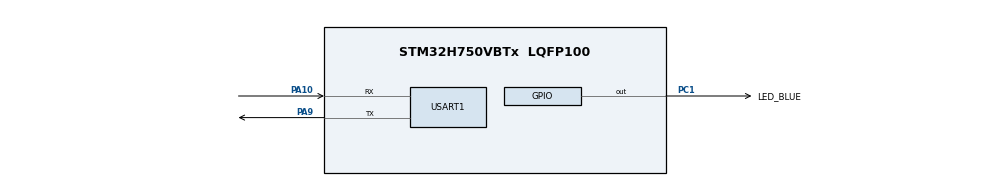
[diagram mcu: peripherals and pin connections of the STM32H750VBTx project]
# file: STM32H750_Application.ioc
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Mcu.Family=STM32H7
Mcu.Name=STM32H750VBTx
Mcu.Package=LQFP100
NVIC.PriorityGroup=NVIC_PRIORITYGROUP_4
PA10.Mode=Asynchronous
PA10.Signal=USART1_RX
PA9.Mode=Asynchronous
PA9.Signal=USART1_TX
PC1.GPIO_Label=LED_BLUE
PC1.Signal=GPIO_Output
ProjectManager.HeapSize=0x200
ProjectManager.StackSize=0x400
ProjectManager.TargetToolchain=STM32CubeIDE
RCC.ADCFreq_Value=129000000
RCC.APB1Freq_Value=120000000
RCC.APB2Freq_Value=120000000
RCC.APB3Freq_Value=120000000
RCC.APB4Freq_Value=120000000
RCC.CortexFreq_Value=480000000
RCC.D1PPRE=RCC_APB3_DIV2
RCC.D2PPRE1=RCC_APB1_DIV2
RCC.D2PPRE2=RCC_APB2_DIV2
RCC.D3PPRE=RCC_APB4_DIV2
RCC.DIVM1=4
RCC.DIVN1=60
RCC.HCLKFreq_Value=240000000
RCC.HPRE=RCC_HCLK_DIV2
RCC.PLL2FRACN=0
RCC.PLL3FRACN=0
RCC.PLLFRACN=0
RCC.PWR_Regulator_Voltage_Scale=PWR_REGULATOR_VOLTAGE_SCALE0
RCC.ProductRev=revV
RCC.SYSCLKFreq_VALUE=480000000
RCC.SYSCLKSource=RCC_SYSCLKSOURCE_PLLCLK
RCC.USBFreq_Value=480000000
USART1.VirtualMode-Asynchronous=VM_ASYNC
board=custom

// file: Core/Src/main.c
/* USER CODE BEGIN Header */
/**
  ******************************************************************************
  * @file           : main.c
  * @brief          : Main program body
  ******************************************************************************
  * @attention
  *
  * Copyright (c) 2026 STMicroelectronics.
  * All rights reserved.
  *
  * This software is licensed under terms that can be found in the LICENSE file
  * in the root directory of this software component.
  * If no LICENSE file comes with this software, it is provided AS-IS.
  *
  ******************************************************************************
  */
/* USER CODE END Header */
#include "main.h"
#include "usart.h"
#include "gpio.h"

/* USER CODE BEGIN Includes */
#include <string.h>
#include <stdio.h>
/* USER CODE END Includes */

void SystemClock_Config(void);
/* USER CODE BEGIN PFP */
void UART_SendString(UART_HandleTypeDef *huart, const char *str);
void UART_SendLine(UART_HandleTypeDef *huart, const char *str);
/* USER CODE END PFP */

/* USER CODE BEGIN 0 */

// ========== UART HELPER FUNCTIONS ==========
// Send a string via UART
void UART_SendString(UART_HandleTypeDef *huart, const char *str)
{
	uint16_t len = strlen(str);
	HAL_UART_Transmit(huart, (uint8_t *)str, len, 1000);
}

// Send a line (string + newline)
void UART_SendLine(UART_HandleTypeDef *huart, const char *str)
{
	UART_SendString(huart, str);
	UART_SendString(huart, "\r\n");
}

/* USER CODE END 0 */

int main(void)
{

  /* MCU Configuration--------------------------------------------------------*/

  /* Reset of all peripherals, Initializes the Flash interface and the Systick. */
  HAL_Init();

  /* Configure the system clock */
  SystemClock_Config();

  /* USER CODE BEGIN SysInit */

  /* Set VTOR to QSPI address where app vector table is located */
  SCB->VTOR = 0x90000000;

  /* USER CODE END SysInit */

  /* Initialize all configured peripherals */
  MX_GPIO_Init();
  MX_USART1_UART_Init();
  /* USER CODE BEGIN 2 */

  /* Debug: Add delay to ensure UART is ready after jump + bootloader DeInit */
  HAL_Delay(200);

  /* Force UART re-enable after bootloader DeInit */
  __HAL_UART_ENABLE(&huart1);

  UART_SendString(&huart1, "\r\n[APP] Starting application...\r\n");
  UART_SendString(&huart1, "=== APPLICATION v0.1 (External Flash / QSPI XIP) ===\r\n");

  char debug_msg[80];
  snprintf(debug_msg, sizeof(debug_msg),
           "[APP] SystemClock = %lu MHz\r\n", SystemCoreClock / 1000000);
  UART_SendString(&huart1, debug_msg);

  /* USER CODE END 2 */

  /* Infinite loop */
  while (1)
  {

    /* USER CODE BEGIN 3 */
      UART_SendString(&huart1, "Application running from external flash!\r\n");
//      HAL_GPIO_TogglePin(GPIOC, LED_BLUE_Pin);
      HAL_Delay(500);
  }
  /* USER CODE END 3 */
}

void SystemClock_Config(void)
{
  RCC_OscInitTypeDef RCC_OscInitStruct = {0};
  RCC_ClkInitTypeDef RCC_ClkInitStruct = {0};

  /** Supply configuration update enable
  */
  HAL_PWREx_ConfigSupply(PWR_LDO_SUPPLY);
  /** Configure the main internal regulator output voltage
  */
  __HAL_PWR_VOLTAGESCALING_CONFIG(PWR_REGULATOR_VOLTAGE_SCALE0);

  while(!__HAL_PWR_GET_FLAG(PWR_FLAG_VOSRDY)) {}
  /** Initializes the RCC Oscillators according to the specified parameters
  * in the RCC_OscInitTypeDef structure.
  */
  RCC_OscInitStruct.OscillatorType = RCC_OSCILLATORTYPE_HSI;
  RCC_OscInitStruct.HSIState = RCC_HSI_DIV1;
  RCC_OscInitStruct.HSICalibrationValue = RCC_HSICALIBRATION_DEFAULT;
  RCC_OscInitStruct.PLL.PLLState = RCC_PLL_ON;
  RCC_OscInitStruct.PLL.PLLSource = RCC_PLLSOURCE_HSI;
  RCC_OscInitStruct.PLL.PLLM = 4;
  RCC_OscInitStruct.PLL.PLLN = 60;
  RCC_OscInitStruct.PLL.PLLP = 2;
  RCC_OscInitStruct.PLL.PLLQ = 2;
  RCC_OscInitStruct.PLL.PLLR = 2;
  RCC_OscInitStruct.PLL.PLLRGE = RCC_PLL1VCIRANGE_3;
  RCC_OscInitStruct.PLL.PLLVCOSEL = RCC_PLL1VCOWIDE;
  RCC_OscInitStruct.PLL.PLLFRACN = 0;
  if (HAL_RCC_OscConfig(&RCC_OscInitStruct) != HAL_OK)
  {
    Error_Handler();
  }
  /** Initializes the CPU, AHB and APB buses clocks
  */
  RCC_ClkInitStruct.ClockType = RCC_CLOCKTYPE_HCLK|RCC_CLOCKTYPE_SYSCLK
                              |RCC_CLOCKTYPE_PCLK1|RCC_CLOCKTYPE_PCLK2
                              |RCC_CLOCKTYPE_D3PCLK1|RCC_CLOCKTYPE_D1PCLK1;
  RCC_ClkInitStruct.SYSCLKSource = RCC_SYSCLKSOURCE_PLLCLK;
  RCC_ClkInitStruct.SYSCLKDivider = RCC_SYSCLK_DIV1;
  RCC_ClkInitStruct.AHBCLKDivider = RCC_HCLK_DIV2;
  RCC_ClkInitStruct.APB3CLKDivider = RCC_APB3_DIV2;
  RCC_ClkInitStruct.APB1CLKDivider = RCC_APB1_DIV2;
  RCC_ClkInitStruct.APB2CLKDivider = RCC_APB2_DIV2;
  RCC_ClkInitStruct.APB4CLKDivider = RCC_APB4_DIV2;

  if (HAL_RCC_ClockConfig(&RCC_ClkInitStruct, FLASH_LATENCY_4) != HAL_OK)
  {
    Error_Handler();
  }
}

void Error_Handler(void)
{
  __disable_irq();
  while (1)
  {
  }
}
